AUTOSAR XML (schema 4-3-0)
package /CAN5/ISignalGroup
  i signal group CAN5_SG_FD5_C100_0: i-signal=[CAN5_AlcLockSta, CAN5_B2VAPlusSta, CAN5_VCUHVILSta], system-signal-group=CAN5_SG_FD5_C100_0
  i signal group CAN5_SG_FD5_C200_0: i-signal=CAN5_SysPowerMode, system-signal-group=CAN5_SG_FD5_C200_0
package /CAN5/Cluster
  can cluster CAN5: baudrate=500, can-fd-baudrate=2000
    can physical channel CAN5: comm-connectors=ConnCAN5
      frame CAN5_DiagFuncReqFT: id 0x7D0, frame-length=8, can-addressing-mode=STANDARD, can-fd-frame-support=false, can-frame-rx-behavior=CAN-20, can-frame-tx-behavior=CAN-20
        n pdu CAN5_DiagFuncReqFT: length=8
      frame CAN5_DiagPhysReqToTBOX: id 0x6D0, frame-length=64, can-addressing-mode=STANDARD, can-fd-frame-support=true, can-frame-rx-behavior=CAN-FD, can-frame-tx-behavior=CAN-FD
        n pdu CAN5_DiagPhysReqToTBOX: length=8
      frame CAN5_DiagRespFromTBOX: id 0x650, frame-length=64, can-addressing-mode=STANDARD, can-fd-frame-support=true, can-frame-rx-behavior=CAN-FD, can-frame-tx-behavior=CAN-FD
        n pdu CAN5_DiagRespFromTBOX: length=8
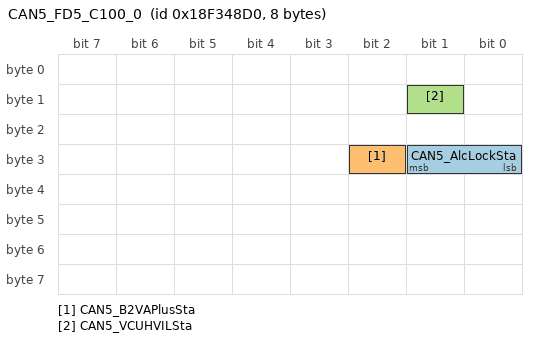
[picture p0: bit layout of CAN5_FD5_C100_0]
      frame CAN5_FD5_C100_0: id 0x18F348D0, frame-length=8, can-addressing-mode=EXTENDED, can-fd-frame-support=false, can-frame-rx-behavior=CAN-20, can-frame-tx-behavior=CAN-20
        pdu CAN5_FD5_C100_0: length=8, minimum-delay=0.0, transmission-mode-true-timing=cyclic-timing=time-period=0.1, unused-bit-pattern=0
          mapping CAN5_SG_FD5_C100_0: i-signal-group=CAN5_SG_FD5_C100_0, start-position=0, transfer-property=PENDING
          signal CAN5_AlcLockSta: start 24, 2 bit, little-endian, i-signal-type=PRIMITIVE, init-value=constant-reference=Init_CAN5_AlcLockSta, base-type=uint8, implementation-data-type=uint8, transfer-property=PENDING
          signal CAN5_B2VAPlusSta: start 26, 1 bit, little-endian, i-signal-type=PRIMITIVE, init-value=constant-reference=Init_CAN5_B2VAPlusSta, base-type=uint8, implementation-data-type=uint8, transfer-property=PENDING
          signal CAN5_VCUHVILSta: start 9, 1 bit, little-endian, i-signal-type=PRIMITIVE, init-value=constant-reference=Init_CAN5_VCUHVILSta, base-type=uint8, implementation-data-type=uint8, transfer-property=PENDING
      frame CAN5_FD5_C200_0: id 0x20D, frame-length=32, can-addressing-mode=STANDARD, can-fd-frame-support=true, can-frame-rx-behavior=CAN-FD, can-frame-tx-behavior=CAN-FD
        pdu CAN5_FD5_C200_0: length=32, minimum-delay=0.0, transmission-mode-true-timing=cyclic-timing=time-period=0.2, unused-bit-pattern=0
          mapping CAN5_SG_FD5_C200_0: i-signal-group=CAN5_SG_FD5_C200_0, start-position=0, transfer-property=PENDING
          signal CAN5_SysPowerMode: start 0, 4 bit, little-endian, i-signal-type=PRIMITIVE, init-value=constant-reference=Init_CAN5_SysPowerMode, base-type=uint8, implementation-data-type=uint8, transfer-property=PENDING
      frame CAN5_NMm_FUSION_TX: id 0x500, frame-length=8, can-addressing-mode=STANDARD, can-fd-frame-support=false, can-frame-rx-behavior=CAN-20, can-frame-tx-behavior=CAN-20
        nm pdu CAN5_NMm_FUSION_TX: length=8, unused-bit-pattern=0
      frame CAN5_NMm_FUSION_RX: id 0x500, frame-length=8, can-addressing-mode=STANDARD, can-fd-frame-support=false, can-frame-rx-behavior=CAN-20, can-frame-tx-behavior=CAN-20
        nm pdu CAN5_NMm_FUSION_RX: length=8, unused-bit-pattern=0
package /CAN5/ConstantSpecification
  6 x constant specification:
    Init_CAN5_AlcLockSta: value-spec=0
    Init_CAN5_B2VAPlusSta: value-spec=0
    Init_CAN5_VCUHVILSta: value-spec=0
    Init_CAN5_SysPowerMode: value-spec=0
    Init_CAN5_SG_FD5_C100_0: value-spec=fields=[Init_CAN5_AlcLockSta, Init_CAN5_B2VAPlusSta, Init_CAN5_VCUHVILSta]
    Init_CAN5_SG_FD5_C200_0: value-spec=fields=constant-reference=Init_CAN5_SysPowerMode
package /CAN5/ImplementationDataTypes
  impl type DT_CAN5_SG_FD5_C100_0: category=STRUCTURE
    element CAN5_AlcLockSta: implementation-data-type=uint8
    element CAN5_B2VAPlusSta: implementation-data-type=uint8
    element CAN5_VCUHVILSta: implementation-data-type=uint8
  impl type DT_CAN5_SG_FD5_C200_0: category=STRUCTURE
    element CAN5_SysPowerMode: implementation-data-type=uint8
